# apollo510 register map
Vendor: Ambiq Micro; Series: Apollo; File version: 1.0
CPU: CM55 r1p1, little endian, MPU, FPU, double-precision FPU, DSP, I-cache, D-cache, VTOR, ITCM, DTCM, 4 interrupt priority bits, 0 interrupts, 8 SAU regions
Registers are 32-bit, read-write, reset 0x0 unless marked. A register's access mark holds for its fields unless they carry their own. Offsets are from the block's base; [hi:lo] are bit positions; {n}, {i} and the like mark numbered series; 'fields as' and 'values as' point back to an identical list.

## GPIO (part 6 of 7) — General Purpose IO
Base 0x40010000
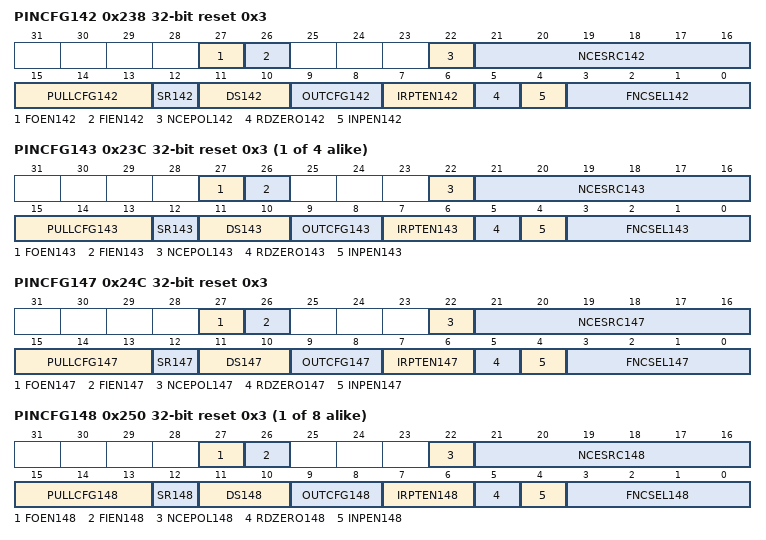
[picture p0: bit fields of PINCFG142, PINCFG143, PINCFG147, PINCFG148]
0x238 PINCFG142 reset 0x3 — Controls the operation of GPIO pin 142.
  [27] FOEN142 — Force output enable active regardless of function selected. Otherwise the selected function will enable the output only when needed
  [26] FIEN142 — Force input enable active regardless of function selected. Otherwise the selected function will enable the input only when needed
  [22] NCEPOL142 — Polarity select for NCE for GPIO 142
    0=LOW (Polarity is active low); 1=HIGH (Polarity is active high)
  [21:16] NCESRC142 — IOMSTR/MSPI N Chip Select 142, DISP control signals DE, CSX, and CS. Polarity is determined by CE_POLARITY field
    {v}=IOM0CE{v} (IOM 0 NCE {v} module) (v=0..3); {v}=IOM1CE{v-4} (IOM 1 NCE {v-4} module) (v=4..7); {v}=IOM2CE{v-8} (IOM 2 NCE {v-8} module) (v=8..11); {v}=IOM3CE{v-12} (IOM 3 NCE {v-12} module) (v=12..15); {v}=IOM4CE{v-16} (IOM 4 NCE {v-16} module) (v=16..19); {v}=IOM5CE{v-20} (IOM 5 NCE {v-20} module) (v=20..23); {v}=IOM6CE{v-24} (IOM 6 NCE {v-24} module) (v=24..27); {v}=IOM7CE{v-28} (IOM 7 NCE {v-28} module) (v=28..31); 48=DC_DPI_DE (DC DPI DE module); 49=DISP_CONT_CSX (DISP CONT CSX module); 50=DC_SPI_CS_N (DC SPI CS_N module); 51=DC_QSPI_CS_N (DC QSPI CS_N module); 52=DC_RESX (DC module RESX)
  [15:13] PULLCFG142 — Pullup/Pulldown configuration for GPIO 142
    0=DIS (No pullup or pulldown selected); 1=PD50K (50K Pulldown selected); 2=PU50K (50K Pullup selected)
  [12] SR142 — Configure high or low drive strength
    0=LDRV (Select the lower of the two drive strength selections); 1=HDRV (Select the higher of the two drive strength selections)
  [11:10] DS142 — Drive strength selection for High Speed GPIO 142
    0=0P12X_0P63X (0.12x output driver selected if SR142 = 0, 0.63x output driver selected if SR142 = 1); 1=0P25X_0P75X (0.25x output driver selected if SR142 = 0, 0.75x output driver selected if SR142 = 1); 2=0P37X_0P88X (0.37x output driver selected if SR142 = 0, 0.88x output driver selected if SR142 = 1); 3=0P5X_1P0X (0.5x output driver selected if SR142 = 0, 1.0x output driver selected if SR142 = 1)
  [9:8] OUTCFG142 — Pin IO mode selection for GPIO pin 142
    0=DIS (Output Disabled); 1=PUSHPULL (Output configured in push pull mode. Will drive 0 and 1 values on pin.); 2=OD (Output configured in open drain mode. Will only drive pin low, tristate otherwise.); 3=TS (Output configured in Tristate-able push pull mode. Will drive 0, 1 of HiZ on pin.)
  [7:6] IRPTEN142 — Interrupt enable for GPIO 142
    0=DIS (Interrupts are disabled for this GPIO); 1=INTFALL (Interrupts are enabled for falling edge transition on this GPIO); 2=INTRISE (Interrupts are enabled for rising edge transitions on this GPIO); 3=INTANY (Interrupts are enabled for any edge transition on this GPIO)
  [5] RDZERO142 — Return 0 for read data on GPIO 142
  [4] INPEN142 — Input enable for GPIO 142
  [3:0] FNCSEL142 — Function select for GPIO pin 142
    0=SWTRACECLK (Serial Wire Debug Trace Clock); 3=GPIO (General purpose I/O); 6=CT142 (Timer/Counter input or output; Selection of direction is done via CTIMER register settings.); 7=NCE142 (IOMSTR N Chip Select. Polarity is determined by CE_POLARITY field); 11=FPIO (Fast PIO)
{0x0+4i} PINCFG{i} reset 0x3 (i=143..146) — Controls the operation of GPIO pin {i}.
  [27] FOEN{i} — Force output enable active regardless of function selected. Otherwise the selected function will enable the output only when needed
  [26] FIEN{i} — Force input enable active regardless of function selected. Otherwise the selected function will enable the input only when needed
  [22] NCEPOL{i} — Polarity select for NCE for GPIO {i}
    values as PINCFG142.NCEPOL142
  [21:16] NCESRC{i} — IOMSTR/MSPI N Chip Select {i}, DISP control signals DE, CSX, and CS. Polarity is determined by CE_POLARITY field
    values as PINCFG142.NCESRC142
  [15:13] PULLCFG{i} — Pullup/Pulldown configuration for GPIO {i}
    values as PINCFG142.PULLCFG142
  [12] SR{i} — Configure high or low drive strength
    values as PINCFG142.SR142
  [11:10] DS{i} — Drive strength selection for High Speed GPIO {i}
    0=0P12X_0P63X (0.12x output driver selected if SR{i} = 0, 0.63x output driver selected if SR{i} = 1); 1=0P25X_0P75X (0.25x output driver selected if SR{i} = 0, 0.75x output driver selected if SR{i} = 1); 2=0P37X_0P88X (0.37x output driver selected if SR{i} = 0, 0.88x output driver selected if SR{i} = 1); 3=0P5X_1P0X (0.5x output driver selected if SR{i} = 0, 1.0x output driver selected if SR{i} = 1)
  [9:8] OUTCFG{i} — Pin IO mode selection for GPIO pin {i}
    values as PINCFG142.OUTCFG142
  [7:6] IRPTEN{i} — Interrupt enable for GPIO {i}
    values as PINCFG142.IRPTEN142
  [5] RDZERO{i} — Return 0 for read data on GPIO {i}
  [4] INPEN{i} — Input enable for GPIO {i}
  [3:0] FNCSEL{i} — Function select for GPIO pin {i}
    0=SWTRACE{i-143} (Serial Wire Debug Trace Output {i-143}); 3=GPIO (General purpose I/O); 6=CT{i} (Timer/Counter input or output; Selection of direction is done via CTIMER register settings.); 7=NCE{i} (IOMSTR N Chip Select. Polarity is determined by CE_POLARITY field); 11=FPIO (Fast PIO)
0x24C PINCFG147 reset 0x3 — Controls the operation of GPIO pin 147.
  [27] FOEN147 — Force output enable active regardless of function selected. Otherwise the selected function will enable the output only when needed
  [26] FIEN147 — Force input enable active regardless of function selected. Otherwise the selected function will enable the input only when needed
  [22] NCEPOL147 — Polarity select for NCE for GPIO 147
    values as PINCFG142.NCEPOL142
  [21:16] NCESRC147 — IOMSTR/MSPI N Chip Select 147, DISP control signals DE, CSX, and CS. Polarity is determined by CE_POLARITY field
    values as PINCFG142.NCESRC142
  [15:13] PULLCFG147 — Pullup/Pulldown configuration for GPIO 147
    0=DIS (No pullup or pulldown selected); 1=PD50K (50K Pulldown selected); 2=PU15K (1.5K Pullup selected); 3=PU6K (6K Pullup selected); 4=PU12K (12K Pullup selected); 5=PU24K (24K Pullup selected); 6=PU50K (50K Pullup selected); 7=PU100K (100K Pullup selected)
  [12] SR147 — Configure the slew rate
  [11:10] DS147 — Drive strength selection for GPIO 147
    0=0P1X (0.1x output driver selected); 1=0P5X (0.5x output driver selected); 2=0P75X (0.75x output driver selected); 3=1P0X (1.0x output driver selected)
  [9:8] OUTCFG147 — Pin IO mode selection for GPIO pin 147
    values as PINCFG142.OUTCFG142
  [7:6] IRPTEN147 — Interrupt enable for GPIO 147
    values as PINCFG142.IRPTEN142
  [5] RDZERO147 — Return 0 for read data on GPIO 147
  [4] INPEN147 — Input enable for GPIO 147
  [3:0] FNCSEL147 — Function select for GPIO pin 147
    0=SWTRACECTL (Serial Wire Debug Trace Control); 3=GPIO (General purpose I/O); 6=CT147 (Timer/Counter input or output; Selection of direction is done via CTIMER register settings.); 7=NCE147 (IOMSTR N Chip Select. Polarity is determined by CE_POLARITY field); 9=MNCE0_0 (MSPI Master 0 nCE 0 Signal); 10=MNCE3_0 (MSPI Master 3 nCE 0 Signal); 11=FPIO (Fast PIO)
{0x0+4i} PINCFG{i} reset 0x3 (i=148..155) — Controls the operation of GPIO pin {i}.
  [27] FOEN{i} — Force output enable active regardless of function selected. Otherwise the selected function will enable the output only when needed
  [26] FIEN{i} — Force input enable active regardless of function selected. Otherwise the selected function will enable the input only when needed
  [22] NCEPOL{i} — Polarity select for NCE for GPIO {i}
    values as PINCFG142.NCEPOL142
  [21:16] NCESRC{i} — IOMSTR/MSPI N Chip Select {i}, DISP control signals DE, CSX, and CS. Polarity is determined by CE_POLARITY field
    values as PINCFG142.NCESRC142
  [15:13] PULLCFG{i} — Pullup/Pulldown configuration for GPIO {i}
    values as PINCFG147.PULLCFG147
  [12] SR{i} — Configure the slew rate
  [11:10] DS{i} — Drive strength selection for GPIO {i}
    0=0P1X (0.1x output driver selected); 1=0P5X (0.5x output driver selected)
  [9:8] OUTCFG{i} — Pin IO mode selection for GPIO pin {i}
    values as PINCFG142.OUTCFG142
  [7:6] IRPTEN{i} — Interrupt enable for GPIO {i}
    values as PINCFG142.IRPTEN142
  [5] RDZERO{i} — Return 0 for read data on GPIO {i}
  [4] INPEN{i} — Input enable for GPIO {i}
  [3:0] FNCSEL{i} — Function select for GPIO pin {i}
    1=DISP_D{i-143} (Display Data {i-143}); 2=DBIB_D{i-140} (Display DBI Data); 3=GPIO (General purpose I/O); 6=CT{i} (Timer/Counter input or output; Selection of direction is done via CTIMER register settings.); 7=NCE{i} (IOMSTR N Chip Select. Polarity is determined by CE_POLARITY field); 11=FPIO (Fast PIO)
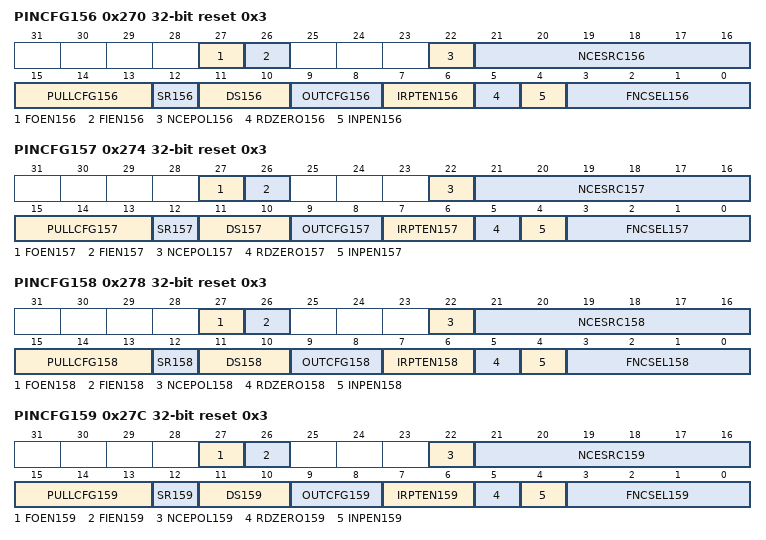
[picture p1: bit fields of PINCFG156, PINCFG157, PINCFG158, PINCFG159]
0x270 PINCFG156 reset 0x3 — Controls the operation of GPIO pin 156.
  [27] FOEN156 — Force output enable active regardless of function selected. Otherwise the selected function will enable the output only when needed
  [26] FIEN156 — Force input enable active regardless of function selected. Otherwise the selected function will enable the input only when needed
  [22] NCEPOL156 — Polarity select for NCE for GPIO 156
    values as PINCFG142.NCEPOL142
  [21:16] NCESRC156 — IOMSTR/MSPI N Chip Select 156, DISP control signals DE, CSX, and CS. Polarity is determined by CE_POLARITY field
    values as PINCFG142.NCESRC142
  [15:13] PULLCFG156 — Pullup/Pulldown configuration for GPIO 156
    values as PINCFG147.PULLCFG147
  [12] SR156 — Configure the slew rate
  [11:10] DS156 — Drive strength selection for GPIO 156
    values as PINCFG147.DS147
  [9:8] OUTCFG156 — Pin IO mode selection for GPIO pin 156
    values as PINCFG142.OUTCFG142
  [7:6] IRPTEN156 — Interrupt enable for GPIO 156
    values as PINCFG142.IRPTEN142
  [5] RDZERO156 — Return 0 for read data on GPIO 156
  [4] INPEN156 — Input enable for GPIO 156
  [3:0] FNCSEL156 — Function select for GPIO pin 156
    0=SDIF0_DAT4 (SD/SDIO/MMC0 Data4 pin); 1=MNCE2_1 (MSPI Master 2 nCE 1 Signal); 3=GPIO (General purpose I/O); 6=CT156 (Timer/Counter input or output; Selection of direction is done via CTIMER register settings.); 7=NCE156 (IOMSTR N Chip Select. Polarity is determined by CE_POLARITY field); 11=FPIO (Fast PIO)
0x274 PINCFG157 reset 0x3 — Controls the operation of GPIO pin 157.
  [27] FOEN157 — Force output enable active regardless of function selected. Otherwise the selected function will enable the output only when needed
  [26] FIEN157 — Force input enable active regardless of function selected. Otherwise the selected function will enable the input only when needed
  [22] NCEPOL157 — Polarity select for NCE for GPIO 157
    values as PINCFG142.NCEPOL142
  [21:16] NCESRC157 — IOMSTR/MSPI N Chip Select 157, DISP control signals DE, CSX, and CS. Polarity is determined by CE_POLARITY field
    values as PINCFG142.NCESRC142
  [15:13] PULLCFG157 — Pullup/Pulldown configuration for GPIO 157
    values as PINCFG147.PULLCFG147
  [12] SR157 — Configure the slew rate
  [11:10] DS157 — Drive strength selection for GPIO 157
    values as PINCFG147.DS147
  [9:8] OUTCFG157 — Pin IO mode selection for GPIO pin 157
    values as PINCFG142.OUTCFG142
  [7:6] IRPTEN157 — Interrupt enable for GPIO 157
    values as PINCFG142.IRPTEN142
  [5] RDZERO157 — Return 0 for read data on GPIO 157
  [4] INPEN157 — Input enable for GPIO 157
  [3:0] FNCSEL157 — Function select for GPIO pin 157
    0=SDIF0_DAT5 (SD/SDIO/MMC0 Data5 pin); 1=MNCE2_0 (MSPI Master 2 nCE 0 Signal); 3=GPIO (General purpose I/O); 6=CT157 (Timer/Counter input or output; Selection of direction is done via CTIMER register settings.); 7=NCE157 (IOMSTR N Chip Select. Polarity is determined by CE_POLARITY field); 11=FPIO (Fast PIO)
0x278 PINCFG158 reset 0x3 — Controls the operation of GPIO pin 158.
  [27] FOEN158 — Force output enable active regardless of function selected. Otherwise the selected function will enable the output only when needed
  [26] FIEN158 — Force input enable active regardless of function selected. Otherwise the selected function will enable the input only when needed
  [22] NCEPOL158 — Polarity select for NCE for GPIO 158
    values as PINCFG142.NCEPOL142
  [21:16] NCESRC158 — IOMSTR/MSPI N Chip Select 158, DISP control signals DE, CSX, and CS. Polarity is determined by CE_POLARITY field
    values as PINCFG142.NCESRC142
  [15:13] PULLCFG158 — Pullup/Pulldown configuration for GPIO 158
    values as PINCFG147.PULLCFG147
  [12] SR158 — Configure the slew rate
  [11:10] DS158 — Drive strength selection for GPIO 158
    values as PINCFG147.DS147
  [9:8] OUTCFG158 — Pin IO mode selection for GPIO pin 158
    values as PINCFG142.OUTCFG142
  [7:6] IRPTEN158 — Interrupt enable for GPIO 158
    values as PINCFG142.IRPTEN142
  [5] RDZERO158 — Return 0 for read data on GPIO 158
  [4] INPEN158 — Input enable for GPIO 158
  [3:0] FNCSEL158 — Function select for GPIO pin 158
    0=SDIF0_DAT6 (SD/SDIO/MMC0 Data6 pin); 3=GPIO (General purpose I/O); 6=CT158 (Timer/Counter input or output; Selection of direction is done via CTIMER register settings.); 7=NCE158 (IOMSTR N Chip Select. Polarity is determined by CE_POLARITY field); 11=FPIO (Fast PIO)
0x27C PINCFG159 reset 0x3 — Controls the operation of GPIO pin 159.
  [27] FOEN159 — Force output enable active regardless of function selected. Otherwise the selected function will enable the output only when needed
  [26] FIEN159 — Force input enable active regardless of function selected. Otherwise the selected function will enable the input only when needed
  [22] NCEPOL159 — Polarity select for NCE for GPIO 159
    values as PINCFG142.NCEPOL142
  [21:16] NCESRC159 — IOMSTR/MSPI N Chip Select 159, DISP control signals DE, CSX, and CS. Polarity is determined by CE_POLARITY field
    values as PINCFG142.NCESRC142
  [15:13] PULLCFG159 — Pullup/Pulldown configuration for GPIO 159
    values as PINCFG147.PULLCFG147
  [12] SR159 — Configure the slew rate
  [11:10] DS159 — Drive strength selection for GPIO 159
    values as PINCFG147.DS147
  [9:8] OUTCFG159 — Pin IO mode selection for GPIO pin 159
    values as PINCFG142.OUTCFG142
  [7:6] IRPTEN159 — Interrupt enable for GPIO 159
    values as PINCFG142.IRPTEN142
  [5] RDZERO159 — Return 0 for read data on GPIO 159
  [4] INPEN159 — Input enable for GPIO 159
  [3:0] FNCSEL159 — Function select for GPIO pin 159
    0=SDIF0_DAT7 (SD/SDIO/MMC0 Data7 pin); 3=GPIO (General purpose I/O); 6=CT159 (Timer/Counter input or output; Selection of direction is done via CTIMER register settings.); 7=NCE159 (IOMSTR N Chip Select. Polarity is determined by CE_POLARITY field); 11=FPIO (Fast PIO)
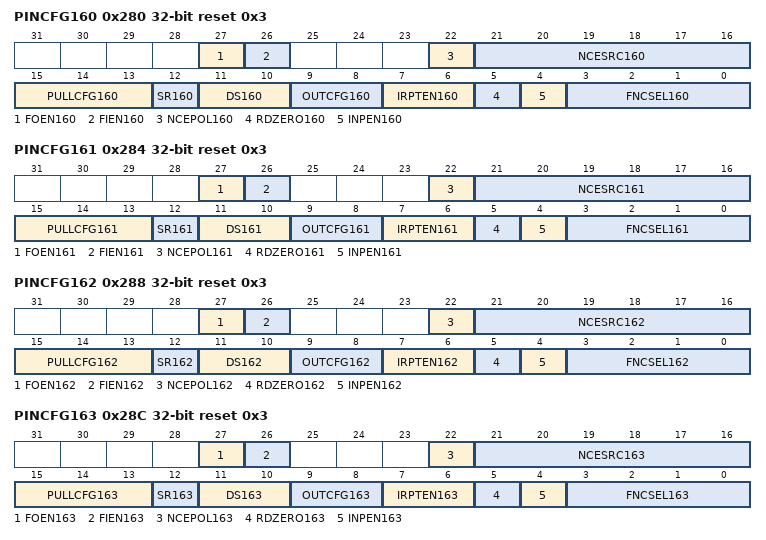
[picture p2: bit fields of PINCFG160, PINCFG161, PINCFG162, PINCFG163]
0x280 PINCFG160 reset 0x3 — Controls the operation of GPIO pin 160.
  [27] FOEN160 — Force output enable active regardless of function selected. Otherwise the selected function will enable the output only when needed
  [26] FIEN160 — Force input enable active regardless of function selected. Otherwise the selected function will enable the input only when needed
  [22] NCEPOL160 — Polarity select for NCE for GPIO 160
    values as PINCFG142.NCEPOL142
  [21:16] NCESRC160 — IOMSTR/MSPI N Chip Select 160, DISP control signals DE, CSX, and CS. Polarity is determined by CE_POLARITY field
    values as PINCFG142.NCESRC142
  [15:13] PULLCFG160 — Pullup/Pulldown configuration for GPIO 160
    values as PINCFG147.PULLCFG147
  [12] SR160 — Configure the slew rate
  [11:10] DS160 — Drive strength selection for GPIO 160
    values as PINCFG147.DS147
  [9:8] OUTCFG160 — Pin IO mode selection for GPIO pin 160
    values as PINCFG142.OUTCFG142
  [7:6] IRPTEN160 — Interrupt enable for GPIO 160
    values as PINCFG142.IRPTEN142
  [5] RDZERO160 — Return 0 for read data on GPIO 160
  [4] INPEN160 — Input enable for GPIO 160
  [3:0] FNCSEL160 — Function select for GPIO pin 160
    0=SDIF0_CMD (SD/SDIO/MMC0 CMD pin); 3=GPIO (General purpose I/O); 6=CT160 (Timer/Counter input or output; Selection of direction is done via CTIMER register settings.); 7=NCE160 (IOMSTR N Chip Select. Polarity is determined by CE_POLARITY field); 11=FPIO (Fast PIO)
0x284 PINCFG161 reset 0x3 — Controls the operation of GPIO pin 161.
  [27] FOEN161 — Force output enable active regardless of function selected. Otherwise the selected function will enable the output only when needed
  [26] FIEN161 — Force input enable active regardless of function selected. Otherwise the selected function will enable the input only when needed
  [22] NCEPOL161 — Polarity select for NCE for GPIO 161
    values as PINCFG142.NCEPOL142
  [21:16] NCESRC161 — IOMSTR/MSPI N Chip Select 161, DISP control signals DE, CSX, and CS. Polarity is determined by CE_POLARITY field
    values as PINCFG142.NCESRC142
  [15:13] PULLCFG161 — Pullup/Pulldown configuration for GPIO 161
    values as PINCFG147.PULLCFG147
  [12] SR161 — Configure the slew rate
  [11:10] DS161 — Drive strength selection for GPIO 161
    values as PINCFG148.DS{i}
  [9:8] OUTCFG161 — Pin IO mode selection for GPIO pin 161
    values as PINCFG142.OUTCFG142
  [7:6] IRPTEN161 — Interrupt enable for GPIO 161
    values as PINCFG142.IRPTEN142
  [5] RDZERO161 — Return 0 for read data on GPIO 161
  [4] INPEN161 — Input enable for GPIO 161
  [3:0] FNCSEL161 — Function select for GPIO pin 161
    3=GPIO (General purpose I/O); 6=CT161 (Timer/Counter input or output; Selection of direction is done via CTIMER register settings.); 7=NCE161 (IOMSTR N Chip Select. Polarity is determined by CE_POLARITY field); 9=I2S1_SDIN (I2S Data input (I2S Master/Slave 1)); 11=FPIO (Fast PIO)
0x288 PINCFG162 reset 0x3 — Controls the operation of GPIO pin 162.
  [27] FOEN162 — Force output enable active regardless of function selected. Otherwise the selected function will enable the output only when needed
  [26] FIEN162 — Force input enable active regardless of function selected. Otherwise the selected function will enable the input only when needed
  [22] NCEPOL162 — Polarity select for NCE for GPIO 162
    values as PINCFG142.NCEPOL142
  [21:16] NCESRC162 — IOMSTR/MSPI N Chip Select 162, DISP control signals DE, CSX, and CS. Polarity is determined by CE_POLARITY field
    values as PINCFG142.NCESRC142
  [15:13] PULLCFG162 — Pullup/Pulldown configuration for GPIO 162
    values as PINCFG147.PULLCFG147
  [12] SR162 — Configure the slew rate
  [11:10] DS162 — Drive strength selection for GPIO 162
    values as PINCFG148.DS{i}
  [9:8] OUTCFG162 — Pin IO mode selection for GPIO pin 162
    values as PINCFG142.OUTCFG142
  [7:6] IRPTEN162 — Interrupt enable for GPIO 162
    values as PINCFG142.IRPTEN142
  [5] RDZERO162 — Return 0 for read data on GPIO 162
  [4] INPEN162 — Input enable for GPIO 162
  [3:0] FNCSEL162 — Function select for GPIO pin 162
    0=SLINT (I2C Slave interrupt); 3=GPIO (General purpose I/O); 6=CT162 (Timer/Counter input or output; Selection of direction is done via CTIMER register settings.); 7=NCE162 (IOMSTR N Chip Select. Polarity is determined by CE_POLARITY field); 11=FPIO (Fast PIO)
0x28C PINCFG163 reset 0x3 — Controls the operation of GPIO pin 163.
  [27] FOEN163 — Force output enable active regardless of function selected. Otherwise the selected function will enable the output only when needed
  [26] FIEN163 — Force input enable active regardless of function selected. Otherwise the selected function will enable the input only when needed
  [22] NCEPOL163 — Polarity select for NCE for GPIO 163
    values as PINCFG142.NCEPOL142
  [21:16] NCESRC163 — IOMSTR/MSPI N Chip Select 163, DISP control signals DE, CSX, and CS. Polarity is determined by CE_POLARITY field
    values as PINCFG142.NCESRC142
  [15:13] PULLCFG163 — Pullup/Pulldown configuration for GPIO 163
    values as PINCFG147.PULLCFG147
  [12] SR163 — Configure the slew rate
  [11:10] DS163 — Drive strength selection for GPIO 163
    values as PINCFG148.DS{i}
  [9:8] OUTCFG163 — Pin IO mode selection for GPIO pin 163
    values as PINCFG142.OUTCFG142
  [7:6] IRPTEN163 — Interrupt enable for GPIO 163
    values as PINCFG142.IRPTEN142
  [5] RDZERO163 — Return 0 for read data on GPIO 163
  [4] INPEN163 — Input enable for GPIO 163
  [3:0] FNCSEL163 — Function select for GPIO pin 163
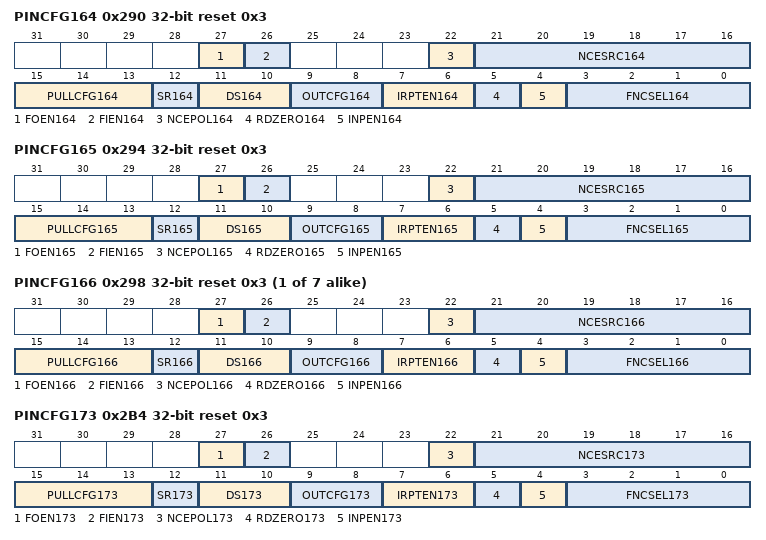
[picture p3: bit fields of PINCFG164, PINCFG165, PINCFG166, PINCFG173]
0x290 PINCFG164 reset 0x3 — Controls the operation of GPIO pin 164.
  [27] FOEN164 — Force output enable active regardless of function selected. Otherwise the selected function will enable the output only when needed
  [26] FIEN164 — Force input enable active regardless of function selected. Otherwise the selected function will enable the input only when needed
  [22] NCEPOL164 — Polarity select for NCE for GPIO 164
    values as PINCFG142.NCEPOL142
  [21:16] NCESRC164 — IOMSTR/MSPI N Chip Select 164, DISP control signals DE, CSX, and CS. Polarity is determined by CE_POLARITY field
    values as PINCFG142.NCESRC142
  [15:13] PULLCFG164 — Pullup/Pulldown configuration for GPIO 164
    values as PINCFG147.PULLCFG147
  [12] SR164 — Configure the slew rate
  [11:10] DS164 — Drive strength selection for GPIO 164
    values as PINCFG148.DS{i}
  [9:8] OUTCFG164 — Pin IO mode selection for GPIO pin 164
    values as PINCFG142.OUTCFG142
  [7:6] IRPTEN164 — Interrupt enable for GPIO 164
    values as PINCFG142.IRPTEN142
  [5] RDZERO164 — Return 0 for read data on GPIO 164
  [4] INPEN164 — Input enable for GPIO 164
  [3:0] FNCSEL164 — Function select for GPIO pin 164
0x294 PINCFG165 reset 0x3 — Controls the operation of GPIO pin 165.
  [27] FOEN165 — Force output enable active regardless of function selected. Otherwise the selected function will enable the output only when needed
  [26] FIEN165 — Force input enable active regardless of function selected. Otherwise the selected function will enable the input only when needed
  [22] NCEPOL165 — Polarity select for NCE for GPIO 165
    values as PINCFG142.NCEPOL142
  [21:16] NCESRC165 — IOMSTR/MSPI N Chip Select 165, DISP control signals DE, CSX, and CS. Polarity is determined by CE_POLARITY field
    values as PINCFG142.NCESRC142
  [15:13] PULLCFG165 — Pullup/Pulldown configuration for GPIO 165
    values as PINCFG147.PULLCFG147
  [12] SR165 — Configure the slew rate
  [11:10] DS165 — Drive strength selection for GPIO 165
    values as PINCFG148.DS{i}
  [9:8] OUTCFG165 — Pin IO mode selection for GPIO pin 165
    values as PINCFG142.OUTCFG142
  [7:6] IRPTEN165 — Interrupt enable for GPIO 165
    values as PINCFG142.IRPTEN142
  [5] RDZERO165 — Return 0 for read data on GPIO 165
  [4] INPEN165 — Input enable for GPIO 165
  [3:0] FNCSEL165 — Function select for GPIO pin 165
    3=GPIO (General purpose I/O); 6=CT165 (Timer/Counter input or output; Selection of direction is done via CTIMER register settings.); 7=NCE165 (IOMSTR N Chip Select. Polarity is determined by CE_POLARITY field); 11=FPIO (Fast PIO)
{0x0+4i} PINCFG{i} reset 0x3 (i=166..172) — Controls the operation of GPIO pin {i}.
  [27] FOEN{i} — Force output enable active regardless of function selected. Otherwise the selected function will enable the output only when needed
  [26] FIEN{i} — Force input enable active regardless of function selected. Otherwise the selected function will enable the input only when needed
  [22] NCEPOL{i} — Polarity select for NCE for GPIO {i}
    values as PINCFG142.NCEPOL142
  [21:16] NCESRC{i} — IOMSTR/MSPI N Chip Select {i}, DISP control signals DE, CSX, and CS. Polarity is determined by CE_POLARITY field
    values as PINCFG142.NCESRC142
  [15:13] PULLCFG{i} — Pullup/Pulldown configuration for GPIO {i}
    values as PINCFG147.PULLCFG147
  [12] SR{i} — Configure the slew rate
  [11:10] DS{i} — Drive strength selection for GPIO {i}
    values as PINCFG148.DS{i}
  [9:8] OUTCFG{i} — Pin IO mode selection for GPIO pin {i}
    values as PINCFG142.OUTCFG142
  [7:6] IRPTEN{i} — Interrupt enable for GPIO {i}
    values as PINCFG142.IRPTEN142
  [5] RDZERO{i} — Return 0 for read data on GPIO {i}
  [4] INPEN{i} — Input enable for GPIO {i}
  [3:0] FNCSEL{i} — Function select for GPIO pin {i}
0x2B4 PINCFG173 reset 0x3 — Controls the operation of GPIO pin 173.
  [27] FOEN173 — Force output enable active regardless of function selected. Otherwise the selected function will enable the output only when needed
  [26] FIEN173 — Force input enable active regardless of function selected. Otherwise the selected function will enable the input only when needed
  [22] NCEPOL173 — Polarity select for NCE for GPIO 173
    values as PINCFG142.NCEPOL142
  [21:16] NCESRC173 — IOMSTR/MSPI N Chip Select 173, DISP control signals DE, CSX, and CS. Polarity is determined by CE_POLARITY field
    values as PINCFG142.NCESRC142
  [15:13] PULLCFG173 — Pullup/Pulldown configuration for GPIO 173
    values as PINCFG147.PULLCFG147
  [12] SR173 — Configure the slew rate
  [11:10] DS173 — Drive strength selection for GPIO 173
    values as PINCFG148.DS{i}
  [9:8] OUTCFG173 — Pin IO mode selection for GPIO pin 173
    values as PINCFG142.OUTCFG142
  [7:6] IRPTEN173 — Interrupt enable for GPIO 173
    values as PINCFG142.IRPTEN142
  [5] RDZERO173 — Return 0 for read data on GPIO 173
  [4] INPEN173 — Input enable for GPIO 173
  [3:0] FNCSEL173 — Function select for GPIO pin 173
    0=SLFDINT (I2C Slave FD1 interrupt); 1=SLFD1INT (I2C Slave FD2 interrupt); 3=GPIO (General purpose I/O); 6=CT173 (Timer/Counter input or output; Selection of direction is done via CTIMER register settings.); 7=NCE173 (IOMSTR N Chip Select. Polarity is determined by CE_POLARITY field); 11=FPIO (Fast PIO)
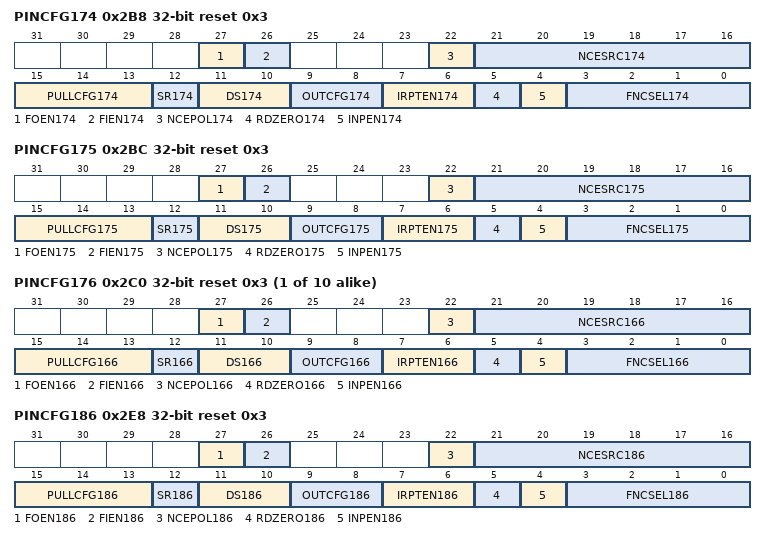
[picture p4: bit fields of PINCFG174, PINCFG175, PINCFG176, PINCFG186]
0x2B8 PINCFG174 reset 0x3 — Controls the operation of GPIO pin 174.
  [27] FOEN174 — Force output enable active regardless of function selected. Otherwise the selected function will enable the output only when needed
  [26] FIEN174 — Force input enable active regardless of function selected. Otherwise the selected function will enable the input only when needed
  [22] NCEPOL174 — Polarity select for NCE for GPIO 174
    values as PINCFG142.NCEPOL142
  [21:16] NCESRC174 — IOMSTR/MSPI N Chip Select 174, DISP control signals DE, CSX, and CS. Polarity is determined by CE_POLARITY field
    values as PINCFG142.NCESRC142
  [15:13] PULLCFG174 — Pullup/Pulldown configuration for GPIO 174
    values as PINCFG147.PULLCFG147
  [12] SR174 — Configure the slew rate
  [11:10] DS174 — Drive strength selection for GPIO 174
    values as PINCFG148.DS{i}
  [9:8] OUTCFG174 — Pin IO mode selection for GPIO pin 174
    values as PINCFG142.OUTCFG142
  [7:6] IRPTEN174 — Interrupt enable for GPIO 174
    values as PINCFG142.IRPTEN142
  [5] RDZERO174 — Return 0 for read data on GPIO 174
  [4] INPEN174 — Input enable for GPIO 174
  [3:0] FNCSEL174 — Function select for GPIO pin 174
0x2BC PINCFG175 reset 0x3 — Controls the operation of GPIO pin 175.
  [27] FOEN175 — Force output enable active regardless of function selected. Otherwise the selected function will enable the output only when needed
  [26] FIEN175 — Force input enable active regardless of function selected. Otherwise the selected function will enable the input only when needed
  [22] NCEPOL175 — Polarity select for NCE for GPIO 175
    values as PINCFG142.NCEPOL142
  [21:16] NCESRC175 — IOMSTR/MSPI N Chip Select 175, DISP control signals DE, CSX, and CS. Polarity is determined by CE_POLARITY field
    values as PINCFG142.NCESRC142
  [15:13] PULLCFG175 — Pullup/Pulldown configuration for GPIO 175
    values as PINCFG147.PULLCFG147
  [12] SR175 — Configure the slew rate
  [11:10] DS175 — Drive strength selection for GPIO 175
    values as PINCFG148.DS{i}
  [9:8] OUTCFG175 — Pin IO mode selection for GPIO pin 175
    values as PINCFG142.OUTCFG142
  [7:6] IRPTEN175 — Interrupt enable for GPIO 175
    values as PINCFG142.IRPTEN142
  [5] RDZERO175 — Return 0 for read data on GPIO 175
  [4] INPEN175 — Input enable for GPIO 175
  [3:0] FNCSEL175 — Function select for GPIO pin 175
    3=GPIO (General purpose I/O); 6=CT175 (Timer/Counter input or output; Selection of direction is done via CTIMER register settings.); 7=NCE175 (IOMSTR N Chip Select. Polarity is determined by CE_POLARITY field); 11=FPIO (Fast PIO)
{0x0+4i} PINCFG{i} reset 0x3 (i=176..185) — Controls the operation of GPIO pin {i}.
  fields as PINCFG166
0x2E8 PINCFG186 reset 0x3 — Controls the operation of GPIO pin 186.
  [27] FOEN186 — Force output enable active regardless of function selected. Otherwise the selected function will enable the output only when needed
  [26] FIEN186 — Force input enable active regardless of function selected. Otherwise the selected function will enable the input only when needed
  [22] NCEPOL186 — Polarity select for NCE for GPIO 186
    values as PINCFG142.NCEPOL142
  [21:16] NCESRC186 — IOMSTR/MSPI N Chip Select 186, DISP control signals DE, CSX, and CS. Polarity is determined by CE_POLARITY field
    values as PINCFG142.NCESRC142
  [15:13] PULLCFG186 — Pullup/Pulldown configuration for GPIO 186
    values as PINCFG147.PULLCFG147
  [12] SR186 — Configure the slew rate
  [11:10] DS186 — Drive strength selection for GPIO 186
    values as PINCFG148.DS{i}
  [9:8] OUTCFG186 — Pin IO mode selection for GPIO pin 186
    values as PINCFG142.OUTCFG142
  [7:6] IRPTEN186 — Interrupt enable for GPIO 186
    values as PINCFG142.IRPTEN142
  [5] RDZERO186 — Return 0 for read data on GPIO 186
  [4] INPEN186 — Input enable for GPIO 186
  [3:0] FNCSEL186 — Function select for GPIO pin 186
    1=DISP_SD (Display RGB Shutdown); 3=GPIO (General purpose I/O); 6=CT186 (Timer/Counter input or output; Selection of direction is done via CTIMER register settings.); 7=NCE186 (IOMSTR N Chip Select. Polarity is determined by CE_POLARITY field); 11=FPIO (Fast PIO)
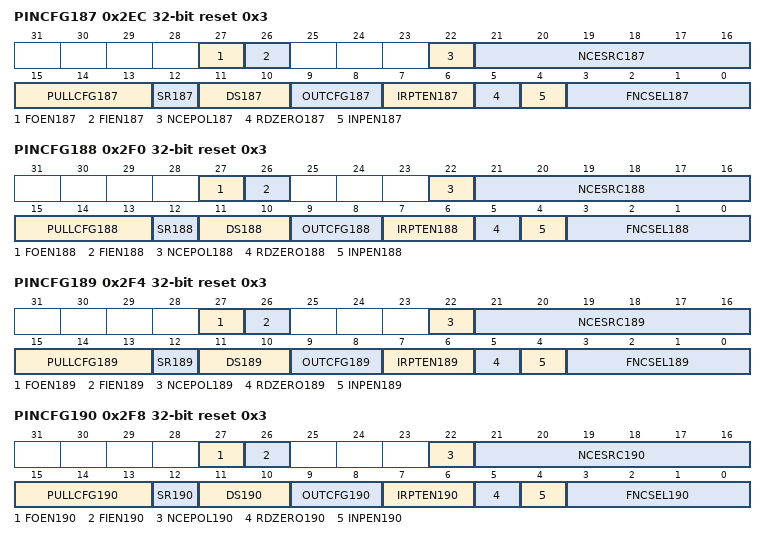
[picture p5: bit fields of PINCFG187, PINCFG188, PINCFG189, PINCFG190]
0x2EC PINCFG187 reset 0x3 — Controls the operation of GPIO pin 187.
  [27] FOEN187 — Force output enable active regardless of function selected. Otherwise the selected function will enable the output only when needed
  [26] FIEN187 — Force input enable active regardless of function selected. Otherwise the selected function will enable the input only when needed
  [22] NCEPOL187 — Polarity select for NCE for GPIO 187
    values as PINCFG142.NCEPOL142
  [21:16] NCESRC187 — IOMSTR/MSPI N Chip Select 187, DISP control signals DE, CSX, and CS. Polarity is determined by CE_POLARITY field
    values as PINCFG142.NCESRC142
  [15:13] PULLCFG187 — Pullup/Pulldown configuration for GPIO 187
    values as PINCFG147.PULLCFG147
  [12] SR187 — Configure the slew rate
  [11:10] DS187 — Drive strength selection for GPIO 187
    values as PINCFG148.DS{i}
  [9:8] OUTCFG187 — Pin IO mode selection for GPIO pin 187
    values as PINCFG142.OUTCFG142
  [7:6] IRPTEN187 — Interrupt enable for GPIO 187
    values as PINCFG142.IRPTEN142
  [5] RDZERO187 — Return 0 for read data on GPIO 187
  [4] INPEN187 — Input enable for GPIO 187
  [3:0] FNCSEL187 — Function select for GPIO pin 187
    1=DISP_DE (Display RGB Data Enable); 3=GPIO (General purpose I/O); 6=CT187 (Timer/Counter input or output; Selection of direction is done via CTIMER register settings.); 7=NCE187 (IOMSTR N Chip Select. Polarity is determined by CE_POLARITY field); 11=FPIO (Fast PIO)
0x2F0 PINCFG188 reset 0x3 — Controls the operation of GPIO pin 188.
  [27] FOEN188 — Force output enable active regardless of function selected. Otherwise the selected function will enable the output only when needed
  [26] FIEN188 — Force input enable active regardless of function selected. Otherwise the selected function will enable the input only when needed
  [22] NCEPOL188 — Polarity select for NCE for GPIO 188
    values as PINCFG142.NCEPOL142
  [21:16] NCESRC188 — IOMSTR/MSPI N Chip Select 188, DISP control signals DE, CSX, and CS. Polarity is determined by CE_POLARITY field
    values as PINCFG142.NCESRC142
  [15:13] PULLCFG188 — Pullup/Pulldown configuration for GPIO 188
    values as PINCFG147.PULLCFG147
  [12] SR188 — Configure the slew rate
  [11:10] DS188 — Drive strength selection for GPIO 188
    values as PINCFG148.DS{i}
  [9:8] OUTCFG188 — Pin IO mode selection for GPIO pin 188
    values as PINCFG142.OUTCFG142
  [7:6] IRPTEN188 — Interrupt enable for GPIO 188
    values as PINCFG142.IRPTEN142
  [5] RDZERO188 — Return 0 for read data on GPIO 188
  [4] INPEN188 — Input enable for GPIO 188
  [3:0] FNCSEL188 — Function select for GPIO pin 188
    1=DISP_CM (Display RGB Reset); 3=GPIO (General purpose I/O); 6=CT188 (Timer/Counter input or output; Selection of direction is done via CTIMER register settings.); 7=NCE188 (IOMSTR N Chip Select. Polarity is determined by CE_POLARITY field); 11=FPIO (Fast PIO)
0x2F4 PINCFG189 reset 0x3 — Controls the operation of GPIO pin 189.
  [27] FOEN189 — Force output enable active regardless of function selected. Otherwise the selected function will enable the output only when needed
  [26] FIEN189 — Force input enable active regardless of function selected. Otherwise the selected function will enable the input only when needed
  [22] NCEPOL189 — Polarity select for NCE for GPIO 189
    values as PINCFG142.NCEPOL142
  [21:16] NCESRC189 — IOMSTR/MSPI N Chip Select 189, DISP control signals DE, CSX, and CS. Polarity is determined by CE_POLARITY field
    values as PINCFG142.NCESRC142
  [15:13] PULLCFG189 — Pullup/Pulldown configuration for GPIO 189
    values as PINCFG147.PULLCFG147
  [12] SR189 — Configure the slew rate
  [11:10] DS189 — Drive strength selection for GPIO 189
    values as PINCFG148.DS{i}
  [9:8] OUTCFG189 — Pin IO mode selection for GPIO pin 189
    values as PINCFG142.OUTCFG142
  [7:6] IRPTEN189 — Interrupt enable for GPIO 189
    values as PINCFG142.IRPTEN142
  [5] RDZERO189 — Return 0 for read data on GPIO 189
  [4] INPEN189 — Input enable for GPIO 189
  [3:0] FNCSEL189 — Function select for GPIO pin 189
    1=DISP_PCLK (Display RGB Pixel Clock); 3=GPIO (General purpose I/O); 6=CT189 (Timer/Counter input or output; Selection of direction is done via CTIMER register settings.); 7=NCE189 (IOMSTR N Chip Select. Polarity is determined by CE_POLARITY field); 11=FPIO (Fast PIO)
0x2F8 PINCFG190 reset 0x3 — Controls the operation of GPIO pin 190.
  [27] FOEN190 — Force output enable active regardless of function selected. Otherwise the selected function will enable the output only when needed
  [26] FIEN190 — Force input enable active regardless of function selected. Otherwise the selected function will enable the input only when needed
  [22] NCEPOL190 — Polarity select for NCE for GPIO 190
    values as PINCFG142.NCEPOL142
  [21:16] NCESRC190 — IOMSTR/MSPI N Chip Select 190, DISP control signals DE, CSX, and CS. Polarity is determined by CE_POLARITY field
    values as PINCFG142.NCESRC142
  [15:13] PULLCFG190 — Pullup/Pulldown configuration for GPIO 190
    values as PINCFG147.PULLCFG147
  [12] SR190 — Configure the slew rate
  [11:10] DS190 — Drive strength selection for GPIO 190
    values as PINCFG148.DS{i}
  [9:8] OUTCFG190 — Pin IO mode selection for GPIO pin 190
    values as PINCFG142.OUTCFG142
  [7:6] IRPTEN190 — Interrupt enable for GPIO 190
    values as PINCFG142.IRPTEN142
  [5] RDZERO190 — Return 0 for read data on GPIO 190
  [4] INPEN190 — Input enable for GPIO 190
  [3:0] FNCSEL190 — Function select for GPIO pin 190
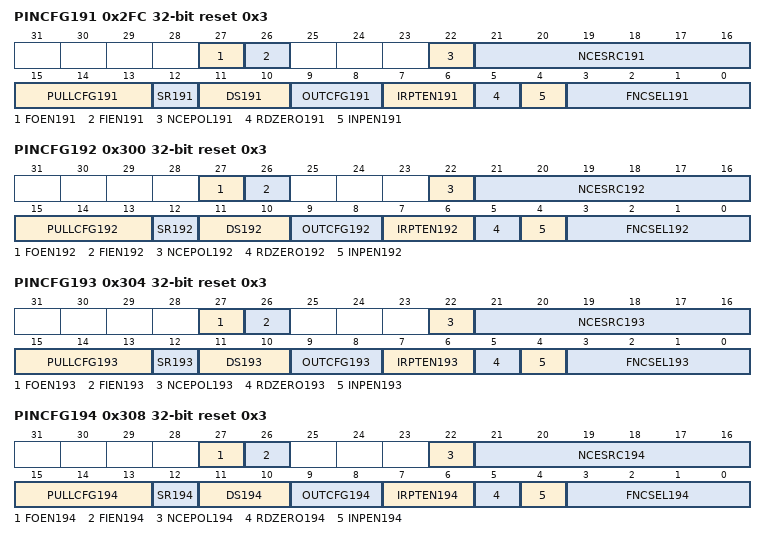
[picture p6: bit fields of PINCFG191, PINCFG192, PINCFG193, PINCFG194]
0x2FC PINCFG191 reset 0x3 — Controls the operation of GPIO pin 191.
  [27] FOEN191 — Force output enable active regardless of function selected. Otherwise the selected function will enable the output only when needed
  [26] FIEN191 — Force input enable active regardless of function selected. Otherwise the selected function will enable the input only when needed
  [22] NCEPOL191 — Polarity select for NCE for GPIO 191
    values as PINCFG142.NCEPOL142
  [21:16] NCESRC191 — IOMSTR/MSPI N Chip Select 191, DISP control signals DE, CSX, and CS. Polarity is determined by CE_POLARITY field
    values as PINCFG142.NCESRC142
  [15:13] PULLCFG191 — Pullup/Pulldown configuration for GPIO 191
    values as PINCFG147.PULLCFG147
  [12] SR191 — Configure the slew rate
  [11:10] DS191 — Drive strength selection for GPIO 191
    values as PINCFG148.DS{i}
  [9:8] OUTCFG191 — Pin IO mode selection for GPIO pin 191
    values as PINCFG142.OUTCFG142
  [7:6] IRPTEN191 — Interrupt enable for GPIO 191
    values as PINCFG142.IRPTEN142
  [5] RDZERO191 — Return 0 for read data on GPIO 191
  [4] INPEN191 — Input enable for GPIO 191
  [3:0] FNCSEL191 — Function select for GPIO pin 191
    3=GPIO (General purpose I/O); 6=CT191 (Timer/Counter input or output; Selection of direction is done via CTIMER register settings.); 7=NCE191 (IOMSTR N Chip Select. Polarity is determined by CE_POLARITY field); 11=FPIO (Fast PIO)
0x300 PINCFG192 reset 0x3 — Controls the operation of GPIO pin 192.
  [27] FOEN192 — Force output enable active regardless of function selected. Otherwise the selected function will enable the output only when needed
  [26] FIEN192 — Force input enable active regardless of function selected. Otherwise the selected function will enable the input only when needed
  [22] NCEPOL192 — Polarity select for NCE for GPIO 192
    values as PINCFG142.NCEPOL142
  [21:16] NCESRC192 — IOMSTR/MSPI N Chip Select 192, DISP control signals DE, CSX, and CS. Polarity is determined by CE_POLARITY field
    values as PINCFG142.NCESRC142
  [15:13] PULLCFG192 — Pullup/Pulldown configuration for GPIO 192
    values as PINCFG147.PULLCFG147
  [12] SR192 — Configure the slew rate
  [11:10] DS192 — Drive strength selection for GPIO 192
    values as PINCFG147.DS147
  [9:8] OUTCFG192 — Pin IO mode selection for GPIO pin 192
    values as PINCFG142.OUTCFG142
  [7:6] IRPTEN192 — Interrupt enable for GPIO 192
    values as PINCFG142.IRPTEN142
  [5] RDZERO192 — Return 0 for read data on GPIO 192
  [4] INPEN192 — Input enable for GPIO 192
  [3:0] FNCSEL192 — Function select for GPIO pin 192
    1=MNCE2_0 (MSPI Master 2 nCE 0 Signal); 3=GPIO (General purpose I/O); 6=CT192 (Timer/Counter input or output; Selection of direction is done via CTIMER register settings.); 7=NCE192 (IOMSTR N Chip Select. Polarity is determined by CE_POLARITY field); 11=FPIO (Fast PIO)
0x304 PINCFG193 reset 0x3 — Controls the operation of GPIO pin 193.
  [27] FOEN193 — Force output enable active regardless of function selected. Otherwise the selected function will enable the output only when needed
  [26] FIEN193 — Force input enable active regardless of function selected. Otherwise the selected function will enable the input only when needed
  [22] NCEPOL193 — Polarity select for NCE for GPIO 193
    values as PINCFG142.NCEPOL142
  [21:16] NCESRC193 — IOMSTR/MSPI N Chip Select 193, DISP control signals DE, CSX, and CS. Polarity is determined by CE_POLARITY field
    values as PINCFG142.NCESRC142
  [15:13] PULLCFG193 — Pullup/Pulldown configuration for GPIO 193
    values as PINCFG147.PULLCFG147
  [12] SR193 — Configure the slew rate
  [11:10] DS193 — Drive strength selection for GPIO 193
    values as PINCFG148.DS{i}
  [9:8] OUTCFG193 — Pin IO mode selection for GPIO pin 193
    values as PINCFG142.OUTCFG142
  [7:6] IRPTEN193 — Interrupt enable for GPIO 193
    values as PINCFG142.IRPTEN142
  [5] RDZERO193 — Return 0 for read data on GPIO 193
  [4] INPEN193 — Input enable for GPIO 193
  [3:0] FNCSEL193 — Function select for GPIO pin 193
0x308 PINCFG194 reset 0x3 — Controls the operation of GPIO pin 194.
  [27] FOEN194 — Force output enable active regardless of function selected. Otherwise the selected function will enable the output only when needed
  [26] FIEN194 — Force input enable active regardless of function selected. Otherwise the selected function will enable the input only when needed
  [22] NCEPOL194 — Polarity select for NCE for GPIO 194
    values as PINCFG142.NCEPOL142
  [21:16] NCESRC194 — IOMSTR/MSPI N Chip Select 194, DISP control signals DE, CSX, and CS. Polarity is determined by CE_POLARITY field
    values as PINCFG142.NCESRC142
  [15:13] PULLCFG194 — Pullup/Pulldown configuration for GPIO 194
    values as PINCFG147.PULLCFG147
  [12] SR194 — Configure the slew rate
  [11:10] DS194 — Drive strength selection for GPIO 194
    values as PINCFG148.DS{i}
  [9:8] OUTCFG194 — Pin IO mode selection for GPIO pin 194
    values as PINCFG142.OUTCFG142
  [7:6] IRPTEN194 — Interrupt enable for GPIO 194
    values as PINCFG142.IRPTEN142
  [5] RDZERO194 — Return 0 for read data on GPIO 194
  [4] INPEN194 — Input enable for GPIO 194
  [3:0] FNCSEL194 — Function select for GPIO pin 194
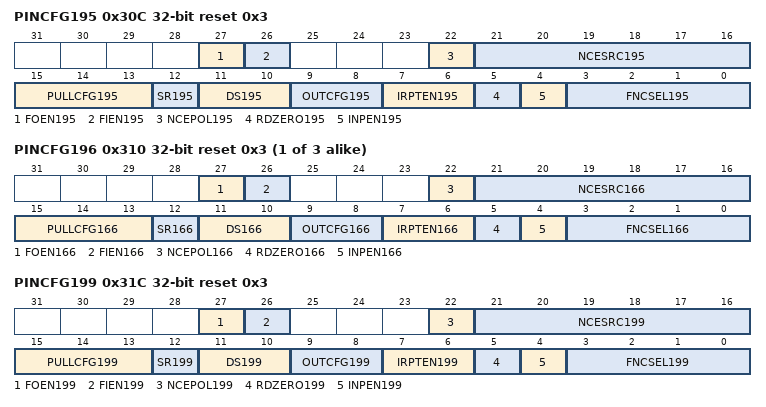
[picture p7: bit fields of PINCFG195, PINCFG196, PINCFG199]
0x30C PINCFG195 reset 0x3 — Controls the operation of GPIO pin 195.
  [27] FOEN195 — Force output enable active regardless of function selected. Otherwise the selected function will enable the output only when needed
  [26] FIEN195 — Force input enable active regardless of function selected. Otherwise the selected function will enable the input only when needed
  [22] NCEPOL195 — Polarity select for NCE for GPIO 195
    values as PINCFG142.NCEPOL142
  [21:16] NCESRC195 — IOMSTR/MSPI N Chip Select 195, DISP control signals DE, CSX, and CS. Polarity is determined by CE_POLARITY field
    values as PINCFG142.NCESRC142
  [15:13] PULLCFG195 — Pullup/Pulldown configuration for GPIO 195
    values as PINCFG147.PULLCFG147
  [12] SR195 — Configure the slew rate
  [11:10] DS195 — Drive strength selection for GPIO 195
    values as PINCFG147.DS147
  [9:8] OUTCFG195 — Pin IO mode selection for GPIO pin 195
    values as PINCFG142.OUTCFG142
  [7:6] IRPTEN195 — Interrupt enable for GPIO 195
    values as PINCFG142.IRPTEN142
  [5] RDZERO195 — Return 0 for read data on GPIO 195
  [4] INPEN195 — Input enable for GPIO 195
  [3:0] FNCSEL195 — Function select for GPIO pin 195
    1=MNCE3_1 (MSPI Master 3 nCE 1 Signal); 2=MNCE3_0 (MSPI Master 3 nCE 0 Signal); 3=GPIO (General purpose I/O); 6=CT195 (Timer/Counter input or output; Selection of direction is done via CTIMER register settings.); 7=NCE195 (IOMSTR N Chip Select. Polarity is determined by CE_POLARITY field); 11=FPIO (Fast PIO)
{0x0+4i} PINCFG{i} reset 0x3 (i=196..198) — Controls the operation of GPIO pin {i}.
  fields as PINCFG166
0x31C PINCFG199 reset 0x3 — Controls the operation of GPIO pin 199.
  [27] FOEN199 — Force output enable active regardless of function selected. Otherwise the selected function will enable the output only when needed
  [26] FIEN199 — Force input enable active regardless of function selected. Otherwise the selected function will enable the input only when needed
  [22] NCEPOL199 — Polarity select for NCE for GPIO 199
    values as PINCFG142.NCEPOL142
  [21:16] NCESRC199 — IOMSTR/MSPI N Chip Select 199, DISP control signals DE, CSX, and CS. Polarity is determined by CE_POLARITY field
    values as PINCFG142.NCESRC142
  [15:13] PULLCFG199 — Pullup/Pulldown configuration for GPIO 199
    values as PINCFG147.PULLCFG147
  [12] SR199 — Configure the slew rate
  [11:10] DS199 — Drive strength selection for GPIO 199
    values as PINCFG147.DS147
  [9:8] OUTCFG199 — Pin IO mode selection for GPIO pin 199
    values as PINCFG142.OUTCFG142
  [7:6] IRPTEN199 — Interrupt enable for GPIO 199
    values as PINCFG142.IRPTEN142
  [5] RDZERO199 — Return 0 for read data on GPIO 199
  [4] INPEN199 — Input enable for GPIO 199
  [3:0] FNCSEL199 — Function select for GPIO pin 199
    1=MNCE0_0 (MSPI Master 0 nCE 0 Signal); 3=GPIO (General purpose I/O); 6=CT199 (Timer/Counter input or output; Selection of direction is done via CTIMER register settings.); 7=NCE199 (IOMSTR N Chip Select. Polarity is determined by CE_POLARITY field); 11=FPIO (Fast PIO)
